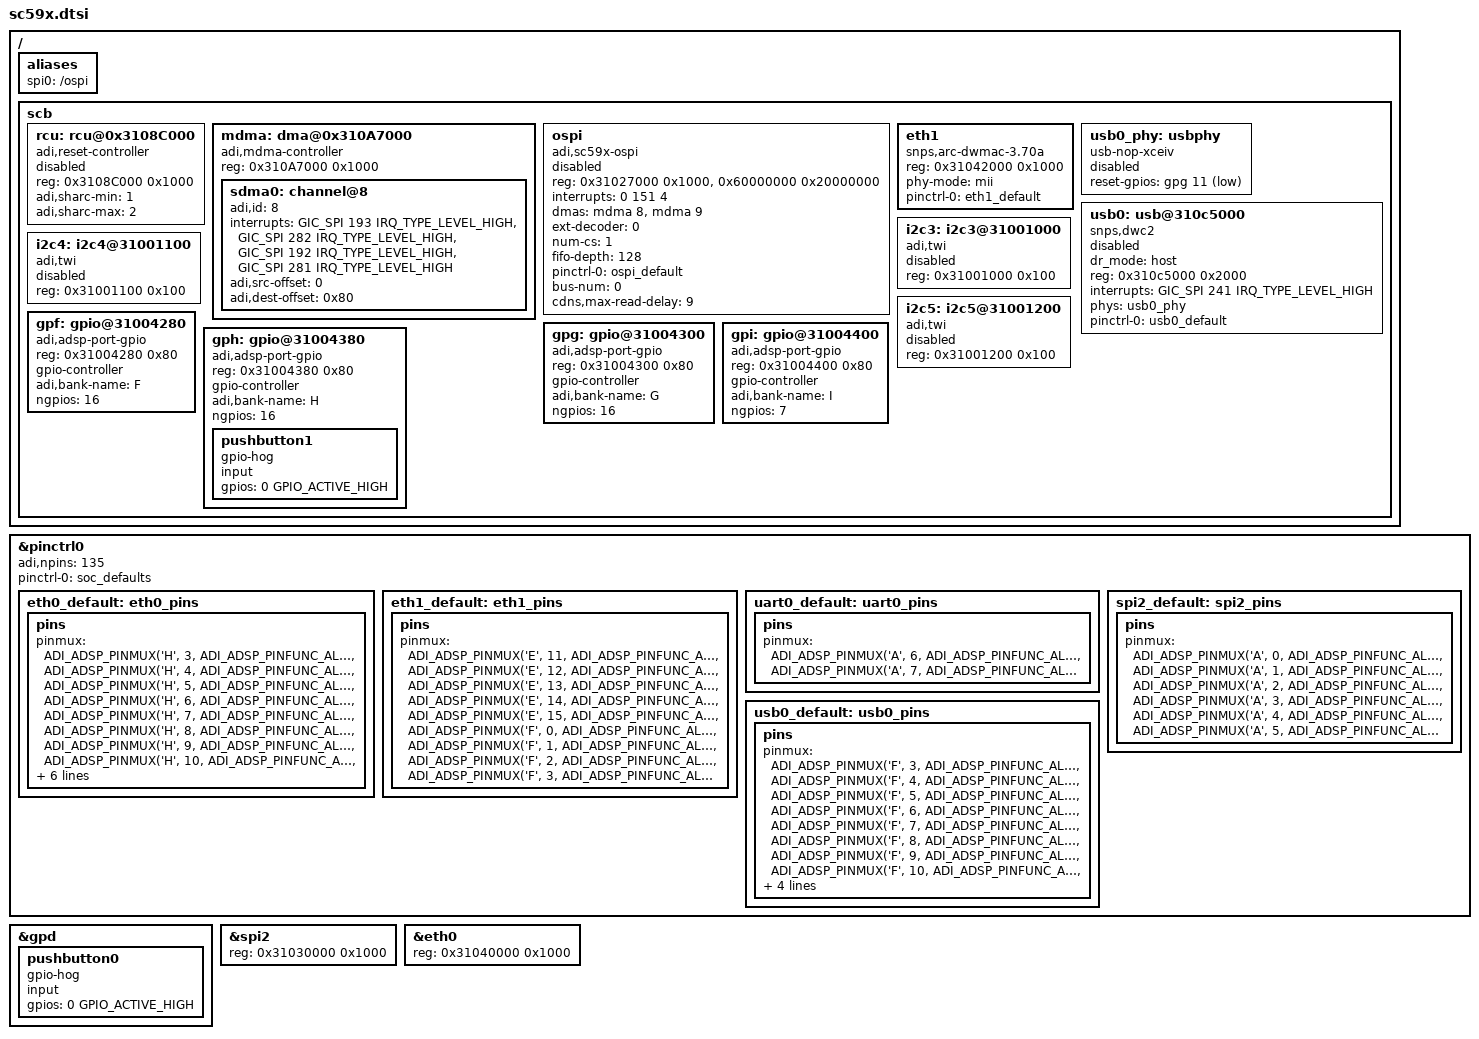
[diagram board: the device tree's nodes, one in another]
// SPDX-License-Identifier: GPL-2.0-or-later
/*
 * (C) Copyright 2024 - Analog Devices, Inc.
 */

/ {

	aliases {
		spi0 = "/ospi";
	};

	scb {
		rcu: rcu@0x3108C000 {
			compatible = "adi,reset-controller", "syscon";
			reg = <0x3108C000 0x1000>;
			adi,sharc-min = <1>;
			adi,sharc-max = <2>;
			status = "disabled";
		};

		mdma: dma@0x310A7000 {
			compatible = "adi,mdma-controller";
			reg = <0x310A7000 0x1000>;
			status = "okay";
			#dma-cells = <1>;

			sdma0: channel@8 {
				adi,id = <8>;
				interrupts = <GIC_SPI 193 IRQ_TYPE_LEVEL_HIGH>,
					<GIC_SPI 282 IRQ_TYPE_LEVEL_HIGH>,
					<GIC_SPI 192 IRQ_TYPE_LEVEL_HIGH>,
					<GIC_SPI 281 IRQ_TYPE_LEVEL_HIGH>;
				interrupt-names = "complete", "error", "complete2", "error2";
				adi,src-offset = <0>;
				adi,dest-offset = <0x80>;
			};
		};

		ospi: ospi {
			compatible = "adi,sc59x-ospi";
			#address-cells = <1>;
			#size-cells = <0>;
			reg = <0x31027000 0x1000>,
			      <0x60000000 0x20000000>;
			interrupts = <0 151 4>;
			dmas = <&mdma 8>, <&mdma 9>;
			dma-names = "src", "dst";
			/*clocks = <&ospi_clk>;*/
			ext-decoder = <0>;	/* external decoder */
			num-cs = <1>;
			fifo-depth = <128>;
			pinctrl-names = "default";
			pinctrl-0 = <&ospi_default>;
			bus-num = <0>;
			clock-names = "ospi";
			cdns,max-read-delay = <9>;
			status = "disabled";
		};

		eth1: eth1 {
			compatible = "snps,arc-dwmac-3.70a";
			reg = <0x31042000 0x1000>;
			phy-mode = "mii";
			pinctrl-names = "default";
			pinctrl-0 = <&eth1_default>;
		};

		usb0_phy: usbphy {
			compatible = "usb-nop-xceiv";
			#phy-cells = <0>;
			reset-gpios = <&gpg 11 GPIO_ACTIVE_LOW>;
			status = "disabled";
		};

		usb0: usb@310c5000 {
			compatible = "snps,dwc2";
			dr_mode = "host";
			reg = <0x310c5000 0x2000>;
			interrupts = <GIC_SPI 241 IRQ_TYPE_LEVEL_HIGH>;
			phys = <&usb0_phy>;
			phy-names = "usb2-phy";
			pinctrl-names = "default";
			pinctrl-0 = <&usb0_default>;
			status = "disabled";
		};

		i2c3: i2c3@31001000 {
			#address-cells = <1>;
			#size-cells = <0>;
			compatible = "adi,twi";
			reg = <0x31001000 0x100>;
			clock-names = "sclk0";
			status = "disabled";
			bootph-pre-ram;
		};

		i2c4: i2c4@31001100 {
			#address-cells = <1>;
			#size-cells = <0>;
			compatible = "adi,twi";
			reg = <0x31001100 0x100>;
			clock-names = "sclk0";
			status = "disabled";
			bootph-pre-ram;
		};

		i2c5: i2c5@31001200 {
			#address-cells = <1>;
			#size-cells = <0>;
			compatible = "adi,twi";
			reg = <0x31001200 0x100>;
			clock-names = "sclk0";
			status = "disabled";
			bootph-pre-ram;
		};
	};
};

&pinctrl0 {
	adi,npins = <135>;

	pinctrl-names = "default";
	pinctrl-0 = <&soc_defaults>;

	eth0_default: eth0_pins {
		pins {
			pinmux = <ADI_ADSP_PINMUX('H', 3, ADI_ADSP_PINFUNC_ALT0)>,
				 <ADI_ADSP_PINMUX('H', 4, ADI_ADSP_PINFUNC_ALT0)>,
				 <ADI_ADSP_PINMUX('H', 5, ADI_ADSP_PINFUNC_ALT0)>,
				 <ADI_ADSP_PINMUX('H', 6, ADI_ADSP_PINFUNC_ALT0)>,
				 <ADI_ADSP_PINMUX('H', 7, ADI_ADSP_PINFUNC_ALT0)>,
				 <ADI_ADSP_PINMUX('H', 8, ADI_ADSP_PINFUNC_ALT0)>,
				 <ADI_ADSP_PINMUX('H', 9, ADI_ADSP_PINFUNC_ALT0)>,
				 <ADI_ADSP_PINMUX('H', 10, ADI_ADSP_PINFUNC_ALT0)>,
				 <ADI_ADSP_PINMUX('H', 11, ADI_ADSP_PINFUNC_ALT0)>,
				 <ADI_ADSP_PINMUX('H', 12, ADI_ADSP_PINFUNC_ALT0)>,
				 <ADI_ADSP_PINMUX('H', 13, ADI_ADSP_PINFUNC_ALT0)>,
				 <ADI_ADSP_PINMUX('H', 14, ADI_ADSP_PINFUNC_ALT0)>,
				 <ADI_ADSP_PINMUX('H', 15, ADI_ADSP_PINFUNC_ALT0)>,
				 <ADI_ADSP_PINMUX('I', 0, ADI_ADSP_PINFUNC_ALT0)>;
		};
	};

	eth1_default: eth1_pins {
		pins {
			pinmux = <ADI_ADSP_PINMUX('E', 11, ADI_ADSP_PINFUNC_ALT0)>,
				 <ADI_ADSP_PINMUX('E', 12, ADI_ADSP_PINFUNC_ALT0)>,
				 <ADI_ADSP_PINMUX('E', 13, ADI_ADSP_PINFUNC_ALT0)>,
				 <ADI_ADSP_PINMUX('E', 14, ADI_ADSP_PINFUNC_ALT0)>,
				 <ADI_ADSP_PINMUX('E', 15, ADI_ADSP_PINFUNC_ALT0)>,
				 <ADI_ADSP_PINMUX('F', 0, ADI_ADSP_PINFUNC_ALT0)>,
				 <ADI_ADSP_PINMUX('F', 1, ADI_ADSP_PINFUNC_ALT0)>,
				 <ADI_ADSP_PINMUX('F', 2, ADI_ADSP_PINFUNC_ALT0)>,
				 <ADI_ADSP_PINMUX('F', 3, ADI_ADSP_PINFUNC_ALT0)>;
		};
	};

	uart0_default: uart0_pins {
		bootph-pre-ram;
		pins {
			bootph-pre-ram;
			pinmux = <ADI_ADSP_PINMUX('A', 6, ADI_ADSP_PINFUNC_ALT1)>,
				 <ADI_ADSP_PINMUX('A', 7, ADI_ADSP_PINFUNC_ALT1)>;
		};
	};

	spi2_default: spi2_pins {
		pins {
			pinmux = <ADI_ADSP_PINMUX('A', 0, ADI_ADSP_PINFUNC_ALT0)>,
				 <ADI_ADSP_PINMUX('A', 1, ADI_ADSP_PINFUNC_ALT0)>,
				 <ADI_ADSP_PINMUX('A', 2, ADI_ADSP_PINFUNC_ALT0)>,
				 <ADI_ADSP_PINMUX('A', 3, ADI_ADSP_PINFUNC_ALT0)>,
				 <ADI_ADSP_PINMUX('A', 4, ADI_ADSP_PINFUNC_ALT0)>,
				 <ADI_ADSP_PINMUX('A', 5, ADI_ADSP_PINFUNC_ALT0)>;
		};
	};

	usb0_default: usb0_pins {
		pins {
			pinmux = <ADI_ADSP_PINMUX('F', 3, ADI_ADSP_PINFUNC_ALT2)>,
				 <ADI_ADSP_PINMUX('F', 4, ADI_ADSP_PINFUNC_ALT2)>,
				 <ADI_ADSP_PINMUX('F', 5, ADI_ADSP_PINFUNC_ALT2)>,
				 <ADI_ADSP_PINMUX('F', 6, ADI_ADSP_PINFUNC_ALT2)>,
				 <ADI_ADSP_PINMUX('F', 7, ADI_ADSP_PINFUNC_ALT2)>,
				 <ADI_ADSP_PINMUX('F', 8, ADI_ADSP_PINFUNC_ALT2)>,
				 <ADI_ADSP_PINMUX('F', 9, ADI_ADSP_PINFUNC_ALT2)>,
				 <ADI_ADSP_PINMUX('F', 10, ADI_ADSP_PINFUNC_ALT2)>,
				 <ADI_ADSP_PINMUX('F', 11, ADI_ADSP_PINFUNC_ALT2)>,
				 <ADI_ADSP_PINMUX('F', 12, ADI_ADSP_PINFUNC_ALT2)>,
				 <ADI_ADSP_PINMUX('F', 13, ADI_ADSP_PINFUNC_ALT2)>,
				 <ADI_ADSP_PINMUX('F', 14, ADI_ADSP_PINFUNC_ALT2)>;
		};
	};
};

/ {
	scb {
		gpf: gpio@31004280 {
			compatible = "adi,adsp-port-gpio";
			reg = <0x31004280 0x80>;
			gpio-controller;
			#gpio-cells = <2>;
			adi,bank-name = "F";
			ngpios = <16>;
			status = "okay";
			bootph-pre-ram;
		};

		gpg: gpio@31004300 {
			compatible = "adi,adsp-port-gpio";
			reg = <0x31004300 0x80>;
			gpio-controller;
			#gpio-cells = <2>;
			adi,bank-name = "G";
			ngpios = <16>;
			status = "okay";
			bootph-pre-ram;
		};

		gph: gpio@31004380 {
			compatible = "adi,adsp-port-gpio";
			reg = <0x31004380 0x80>;
			gpio-controller;
			#gpio-cells = <2>;
			adi,bank-name = "H";
			ngpios = <16>;
			status = "okay";
			bootph-pre-ram;
		};

		gpi: gpio@31004400 {
			compatible = "adi,adsp-port-gpio";
			reg = <0x31004400 0x80>;
			gpio-controller;
			#gpio-cells = <2>;
			adi,bank-name = "I";
			ngpios = <7>;
			status = "okay";
			bootph-pre-ram;
		};
	};
};

&gpd {
	pushbutton0 {
		gpio-hog;
		input;
		gpios = <0 GPIO_ACTIVE_HIGH>;
	};
};

&gph {
	pushbutton1 {
		gpio-hog;
		input;
		gpios = <0 GPIO_ACTIVE_HIGH>;
	};
};

&spi2 {
	reg = <0x31030000 0x1000>;
};

&eth0 {
	reg = <0x31040000 0x1000>;
};
